# RP2350 register map
Vendor: Raspberry Pi; Series: RP; File version: 0.1
CPU: CM33 r1p0, little endian, MPU, FPU, DSP, VTOR, 4 interrupt priority bits, 52 interrupts, 8 SAU regions
Registers are 32-bit, read-write, reset 0x0 unless marked. A register's access mark holds for its fields unless they carry their own. Offsets are from the block's base; [hi:lo] are bit positions; {n}, {i} and the like mark numbered series; 'fields as' and 'values as' point back to an identical list.

## POWMAN — Controls vreg, bor, lposc, chip resets & xosc startup, powman and provides scratch register for general use and for bootcode use
Base 0x40100000
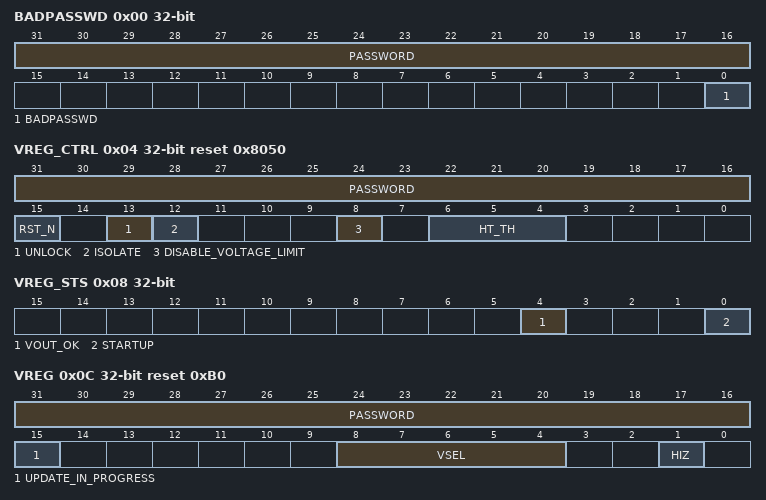
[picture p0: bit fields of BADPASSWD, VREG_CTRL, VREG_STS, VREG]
0x00 BADPASSWD — Indicates a bad password has been used
  [31:16] PASSWORD wo range 0x5AFE..0x5AFE — Write 0x5AFE with every write, or the write is ignored
    0x5AFE=PASSWORD
  [0] BADPASSWD write-1-clears
0x04 VREG_CTRL reset 0x8050 — Voltage Regulator Control
  [31:16] PASSWORD wo range 0x5AFE..0x5AFE — Write 0x5AFE with every write, or the write is ignored
    0x5AFE=PASSWORD
  [15] RST_N — returns the regulator to its startup settings 0 - reset 1 - not reset (default)
  [13] UNLOCK — unlocks the VREG control interface after power up 0 - Locked (default) 1 - Unlocked It cannot be relocked when it is unlocked.
  [12] ISOLATE — isolates the VREG control interface 0 - not isolated (default) 1 - isolated
  [8] DISABLE_VOLTAGE_LIMIT — 0=not disabled, 1=enabled
  [6:4] HT_TH — high temperature protection threshold regulator power transistors are disabled when junction temperature exceeds threshold 000 - 100C 001 - 105C 010 - 110C 011 - 115C 100 - 120C 101 - 125C 110 - 135C 111 - 150C
0x08 VREG_STS — Voltage Regulator Status
  [4] VOUT_OK ro — output regulation status 0=not in regulation, 1=in regulation
  [0] STARTUP ro — startup status 0=startup complete, 1=starting up
0x0C VREG reset 0xB0 — Voltage Regulator Settings
  [31:16] PASSWORD wo range 0x5AFE..0x5AFE — Write 0x5AFE with every write, or the write is ignored
    0x5AFE=PASSWORD
  [15] UPDATE_IN_PROGRESS ro — regulator state is being updated writes to the vreg register will be ignored when this field is set
  [8:4] VSEL — output voltage select the regulator output voltage is limited to 1.3V unless the voltage limit is disabled using the disable_voltage_limit field in the vreg_ctrl register 00000 - 0.55V 00001 - 0.60V 00010 - 0.65V 00011 - 0.70V 00100 - 0.75V 00101 - 0.80V 00110 - 0.85V 00111 - 0.90V 01000 - 0.95V 01001 - 1.00V 01010 - 1.05V 01011 - 1.10V (default) 01100 - 1.15V 01101 - 1.20V 01110 - 1.25V 01111 - 1.30V 10000 - 1.35V 10001 - 1.40V 10010 - 1.50V 10011 - 1.60V 10100 - 1.65V 10101 - 1.70V 10110 - 1.80V 10111 - 1.90V 11000 - 2.00V 11001 - 2.35V 11010 - 2.50V 11011 - 2.65V 11100 - 2.80V 11101 - 3.00V 11110 - 3.15V 11111 - 3.30V
  [1] HIZ — high impedance mode select 0=not in high impedance mode, 1=in high impedance mode
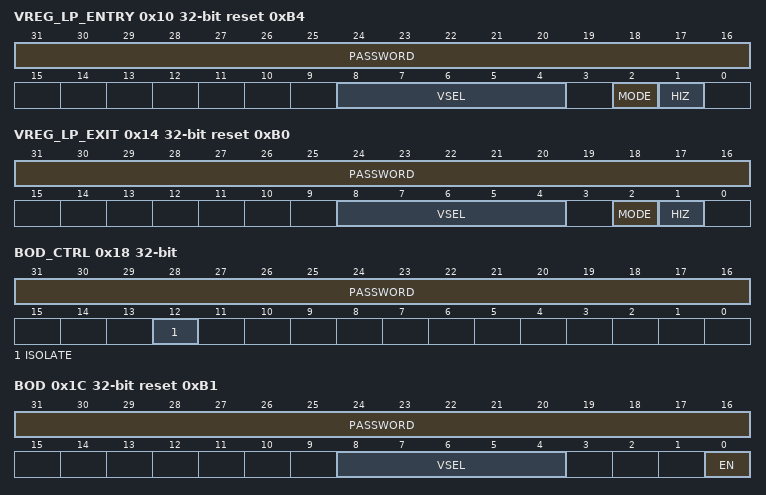
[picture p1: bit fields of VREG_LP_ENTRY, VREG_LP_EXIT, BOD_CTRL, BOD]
0x10 VREG_LP_ENTRY reset 0xB4 — Voltage Regulator Low Power Entry Settings
  [31:16] PASSWORD wo range 0x5AFE..0x5AFE — Write 0x5AFE with every write, or the write is ignored
    0x5AFE=PASSWORD
  [8:4] VSEL — output voltage select the regulator output voltage is limited to 1.3V unless the voltage limit is disabled using the disable_voltage_limit field in the vreg_ctrl register 00000 - 0.55V 00001 - 0.60V 00010 - 0.65V 00011 - 0.70V 00100 - 0.75V 00101 - 0.80V 00110 - 0.85V 00111 - 0.90V 01000 - 0.95V 01001 - 1.00V 01010 - 1.05V 01011 - 1.10V (default) 01100 - 1.15V 01101 - 1.20V 01110 - 1.25V 01111 - 1.30V 10000 - 1.35V 10001 - 1.40V 10010 - 1.50V 10011 - 1.60V 10100 - 1.65V 10101 - 1.70V 10110 - 1.80V 10111 - 1.90V 11000 - 2.00V 11001 - 2.35V 11010 - 2.50V 11011 - 2.65V 11100 - 2.80V 11101 - 3.00V 11110 - 3.15V 11111 - 3.30V
  [2] MODE — selects either normal (switching) mode or low power (linear) mode low power mode can only be selected for output voltages up to 1.3V 0 = normal mode (switching) 1 = low power mode (linear)
  [1] HIZ — high impedance mode select 0=not in high impedance mode, 1=in high impedance mode
0x14 VREG_LP_EXIT reset 0xB0 — Voltage Regulator Low Power Exit Settings
  fields as VREG_LP_ENTRY
0x18 BOD_CTRL — Brown-out Detection Control
  [31:16] PASSWORD wo range 0x5AFE..0x5AFE — Write 0x5AFE with every write, or the write is ignored
    0x5AFE=PASSWORD
  [12] ISOLATE — isolates the brown-out detection control interface 0 - not isolated (default) 1 - isolated
0x1C BOD reset 0xB1 — Brown-out Detection Settings
  [31:16] PASSWORD wo range 0x5AFE..0x5AFE — Write 0x5AFE with every write, or the write is ignored
    0x5AFE=PASSWORD
  [8:4] VSEL — threshold select 00000 - 0.473V 00001 - 0.516V 00010 - 0.559V 00011 - 0.602V 00100 - 0.645VS 00101 - 0.688V 00110 - 0.731V 00111 - 0.774V 01000 - 0.817V 01001 - 0.860V (default) 01010 - 0.903V 01011 - 0.946V 01100 - 0.989V 01101 - 1.032V 01110 - 1.075V 01111 - 1.118V 10000 - 1.161 10001 - 1.204V
  [0] EN — enable brown-out detection 0=not enabled, 1=enabled
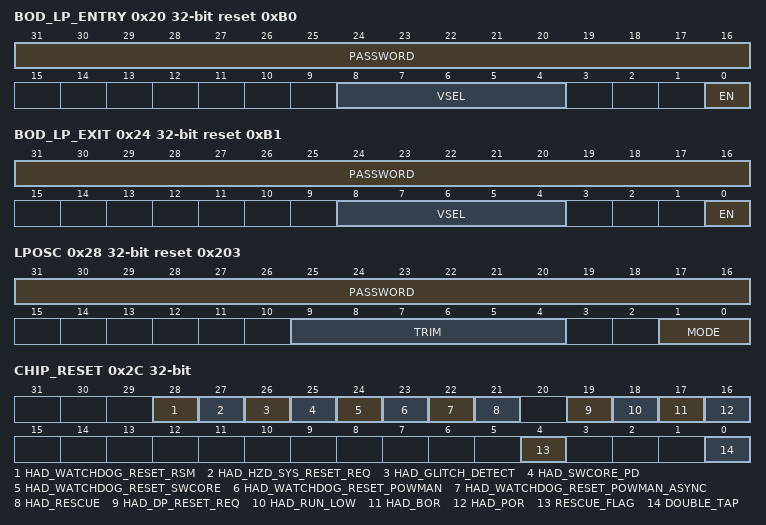
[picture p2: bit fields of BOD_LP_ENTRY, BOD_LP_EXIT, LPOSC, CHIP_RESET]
0x20 BOD_LP_ENTRY reset 0xB0 — Brown-out Detection Low Power Entry Settings
  fields as BOD
0x24 BOD_LP_EXIT reset 0xB1 — Brown-out Detection Low Power Exit Settings
  fields as BOD
0x28 LPOSC reset 0x203 — Low power oscillator control register.
  [31:16] PASSWORD wo range 0x5AFE..0x5AFE — Write 0x5AFE with every write, or the write is ignored
    0x5AFE=PASSWORD
  [9:4] TRIM — Frequency trim - the trim step is typically 1% of the reset frequency, but can be up to 3%
  [1:0] MODE — This feature has been removed
0x2C CHIP_RESET — Chip reset control and status
  [28] HAD_WATCHDOG_RESET_RSM ro — Last reset was a watchdog timeout which was configured to reset the power-on state machine This resets: double_tap flag no DP no RPAP no rescue_flag no timer no powman no swcore no psm yes and does not change the power state
  [27] HAD_HZD_SYS_RESET_REQ ro — Last reset was a system reset from the hazard debugger This resets: double_tap flag no DP no RPAP no rescue_flag no timer no powman no swcore no psm yes and does not change the power state
  [26] HAD_GLITCH_DETECT ro — Last reset was due to a power supply glitch This resets: double_tap flag no DP no RPAP no rescue_flag no timer no powman no swcore no psm yes and does not change the power state
  [25] HAD_SWCORE_PD ro — Last reset was a switched core powerdown This resets: double_tap flag no DP no RPAP no rescue_flag no timer no powman no swcore yes psm yes then starts the power sequencer
  [24] HAD_WATCHDOG_RESET_SWCORE ro — Last reset was a watchdog timeout which was configured to reset the switched-core This resets: double_tap flag no DP no RPAP no rescue_flag no timer no powman no swcore yes psm yes then starts the power sequencer
  [23] HAD_WATCHDOG_RESET_POWMAN ro — Last reset was a watchdog timeout which was configured to reset the power manager This resets: double_tap flag no DP no RPAP no rescue_flag no timer yes powman yes swcore yes psm yes then starts the power sequencer
  [22] HAD_WATCHDOG_RESET_POWMAN_ASYNC ro — Last reset was a watchdog timeout which was configured to reset the power manager asynchronously This resets: double_tap flag no DP no RPAP no rescue_flag no timer yes powman yes swcore yes psm yes then starts the power sequencer
  [21] HAD_RESCUE ro — Last reset was a rescue reset from the debugger This resets: double_tap flag no DP no RPAP no rescue_flag no, it sets this flag timer yes powman yes swcore yes psm yes then starts the power sequencer
  [19] HAD_DP_RESET_REQ ro — Last reset was an reset request from the arm debugger This resets: double_tap flag no DP no RPAP no rescue_flag yes timer yes powman yes swcore yes psm yes then starts the power sequencer
  [18] HAD_RUN_LOW ro — Last reset was from the RUN pin This resets: double_tap flag no DP yes RPAP yes rescue_flag yes timer yes powman yes swcore yes psm yes then starts the power sequencer
  [17] HAD_BOR ro — Last reset was from the brown-out detection block This resets: double_tap flag yes DP yes RPAP yes rescue_flag yes timer yes powman yes swcore yes psm yes then starts the power sequencer
  [16] HAD_POR ro — Last reset was from the power-on reset This resets: double_tap flag yes DP yes RPAP yes rescue_flag yes timer yes powman yes swcore yes psm yes then starts the power sequencer
  [4] RESCUE_FLAG write-1-clears — This is set by a rescue reset from the RP-AP. Its purpose is to halt before the bootrom before booting from flash in order to recover from a boot lock-up. The debugger can then attach once the bootrom has been halted and flash some working code that does not lock up.
  [0] DOUBLE_TAP — This flag is set by double-tapping RUN. It tells bootcode to go into the bootloader.
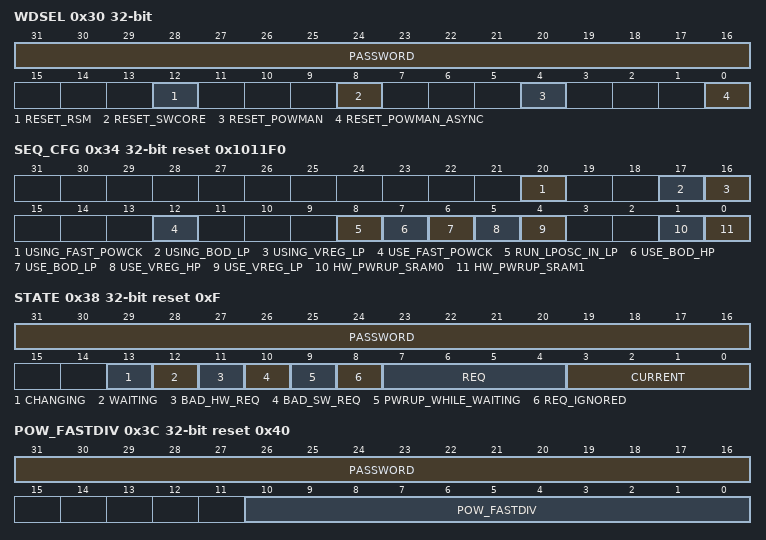
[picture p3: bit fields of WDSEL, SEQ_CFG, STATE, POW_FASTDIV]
0x30 WDSEL — Allows a watchdog reset to reset the internal state of powman in addition to the power-on state machine (PSM). Note that powman ignores watchdog resets that do not select at least the CLOCKS stage or earlier stages in the PSM. If using these bits, it's recommended to set PSM_WDSEL to all-ones in addition to the desired bits in this register. Failing to select CLOCKS or earlier will result in the POWMAN_WDSEL register having no effect.
  [31:16] PASSWORD wo range 0x5AFE..0x5AFE — Write 0x5AFE with every write, or the write is ignored
    0x5AFE=PASSWORD
  [12] RESET_RSM — If set to 1, a watchdog reset will run the full power-on state machine (PSM) sequence From a user perspective it is the same as setting RSM_WDSEL_PROC_COLD From a hardware debug perspective it has the same effect as a reset from a glitch detector
  [8] RESET_SWCORE — If set to 1, a watchdog reset will reset the switched core power domain and run the full power-on state machine (PSM) sequence From a user perspective it is the same as setting RSM_WDSEL_PROC_COLD From a hardware debug perspective it has the same effect as a power-on reset for the switched core power domain
  [4] RESET_POWMAN — If set to 1, a watchdog reset will restore powman defaults, reset the timer, reset the switched core power domain and run the full power-on state machine (PSM) sequence This relies on clk_ref running. Use reset_powman_async if that may not be true
  [0] RESET_POWMAN_ASYNC — If set to 1, a watchdog reset will restore powman defaults, reset the timer, reset the switched core domain and run the full power-on state machine (PSM) sequence This does not rely on clk_ref running
0x34 SEQ_CFG reset 0x1011F0 — For configuration of the power sequencer Writes are ignored while POWMAN_STATE_CHANGING=1
  [20] USING_FAST_POWCK ro — 0 indicates the POWMAN clock is running from the low power oscillator (32kHz) 1 indicates the POWMAN clock is running from the reference clock (2-50MHz)
  [17] USING_BOD_LP ro — Indicates the brown-out detector (BOD) mode 0 = BOD high power mode which is the default 1 = BOD low power mode
  [16] USING_VREG_LP ro — Indicates the voltage regulator (VREG) mode 0 = VREG high power mode which is the default 1 = VREG low power mode
  [12] USE_FAST_POWCK — selects the reference clock (clk_ref) as the source of the POWMAN clock when switched-core is powered. The POWMAN clock always switches to the slow clock (lposc) when switched-core is powered down because the fast clock stops running. 0 always run the POWMAN clock from the slow clock (lposc) 1 run the POWMAN clock from the fast clock when available This setting takes effect when a power up sequence is next run
  [8] RUN_LPOSC_IN_LP — Set to 0 to stop the low power osc when the switched-core is powered down, which is unwise if using it to clock the timer This setting takes effect when the swcore is next powered down
  [7] USE_BOD_HP — Set to 0 to prevent automatic switching to bod high power mode when switched-core is powered up This setting takes effect when the swcore is next powered up
  [6] USE_BOD_LP — Set to 0 to prevent automatic switching to bod low power mode when switched-core is powered down This setting takes effect when the swcore is next powered down
  [5] USE_VREG_HP — Set to 0 to prevent automatic switching to vreg high power mode when switched-core is powered up This setting takes effect when the swcore is next powered up
  [4] USE_VREG_LP — Set to 0 to prevent automatic switching to vreg low power mode when switched-core is powered down This setting takes effect when the swcore is next powered down
  [1] HW_PWRUP_SRAM0 — Specifies the power state of SRAM0 when powering up swcore from a low power state (P1.xxx) to a high power state (P0.0xx). 0=power-up 1=no change
  [0] HW_PWRUP_SRAM1 — Specifies the power state of SRAM1 when powering up swcore from a low power state (P1.xxx) to a high power state (P0.0xx). 0=power-up 1=no change
0x38 STATE reset 0xF — This register controls the power state of the 4 power domains. The current power state is indicated in POWMAN_STATE_CURRENT which is read-only. To change the state, write to POWMAN_STATE_REQ. The coding of POWMAN_STATE_CURRENT & POWMAN_STATE_REQ corresponds to the power states defined in the datasheet: bit 3 = SWCORE bit 2 = XIP cache bit 1 = SRAM0 bit 0 = SRAM1 0 = powered up 1 = powered down When POWMAN_STATE_REQ is written, the POWMAN_STATE_WAITING flag is set while the Power Manager determines what is required. If an invalid transition is requested the Power Manager will still register the request in POWMAN_STATE_REQ but will also set the POWMAN_BAD_REQ flag. It will then implement the power-up requests and ignore the power down requests. To do nothing would risk entering an unrecoverable lock-up state. Invalid requests are: any combination of power up and power down requests any request that results in swcore being powered and xip unpowered If the request is to power down the switched-core domain then POWMAN_STATE_WAITING stays active until the processors halt. During this time the POWMAN_STATE_REQ field can be re-written to change or cancel the request. When the power state transition begins the POWMAN_STATE_WAITING_flag is cleared, the POWMAN_STATE_CHANGING flag is set and POWMAN register writes are ignored until the transition completes.
  [31:16] PASSWORD wo range 0x5AFE..0x5AFE — Write 0x5AFE with every write, or the write is ignored
    0x5AFE=PASSWORD
  [13] CHANGING ro — Indicates a power state change is in progress
  [12] WAITING ro — Indicates the power manager has received a state change request and is waiting for other actions to complete before executing it
  [11] BAD_HW_REQ ro — Invalid hardware initiated state request, power up requests actioned, power down requests ignored
  [10] BAD_SW_REQ ro — Invalid software initiated state request ignored
  [9] PWRUP_WHILE_WAITING write-1-clears — Indicates that a power state change request was ignored because of a pending power state change request
  [8] REQ_IGNORED write-1-clears — Indicates that a software state change request was ignored because it clashed with an ongoing hardware or debugger request
  [7:4] REQ — This is written by software or hardware to request a new power state
  [3:0] CURRENT ro — Indicates the current power state
0x3C POW_FASTDIV reset 0x40
  [31:16] PASSWORD wo range 0x5AFE..0x5AFE — Write 0x5AFE with every write, or the write is ignored
    0x5AFE=PASSWORD
  [10:0] POW_FASTDIV — divides the POWMAN clock to provide a tick for the delay module and state machines when clk_pow is running from the slow clock it is not divided when clk_pow is running from the fast clock it is divided by tick_div
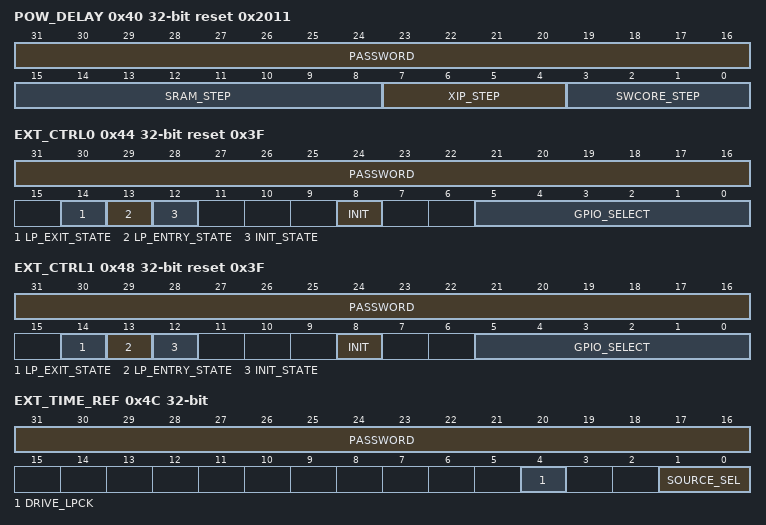
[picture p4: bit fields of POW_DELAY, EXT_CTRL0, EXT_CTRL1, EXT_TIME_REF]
0x40 POW_DELAY reset 0x2011 — power state machine delays
  [31:16] PASSWORD wo range 0x5AFE..0x5AFE — Write 0x5AFE with every write, or the write is ignored
    0x5AFE=PASSWORD
  [15:8] SRAM_STEP — timing between the sram0 and sram1 power state machine steps measured in units of the powman tick period (>=1us), 0 gives a delay of 1 unit
  [7:4] XIP_STEP — timing between the xip power state machine steps measured in units of the lposc period, 0 gives a delay of 1 unit
  [3:0] SWCORE_STEP — timing between the swcore power state machine steps measured in units of the lposc period, 0 gives a delay of 1 unit
0x44 EXT_CTRL0 reset 0x3F — Configures a gpio as a power mode aware control output
  [31:16] PASSWORD wo range 0x5AFE..0x5AFE — Write 0x5AFE with every write, or the write is ignored
    0x5AFE=PASSWORD
  [14] LP_EXIT_STATE — output level when exiting the low power state
  [13] LP_ENTRY_STATE — output level when entering the low power state
  [12] INIT_STATE
  [8] INIT
  [5:0] GPIO_SELECT — selects from gpio 0->30 set to 31 to disable this feature
0x48 EXT_CTRL1 reset 0x3F — Configures a gpio as a power mode aware control output
  fields as EXT_CTRL0
0x4C EXT_TIME_REF — Select a GPIO to use as a time reference, the source can be used to drive the low power clock at 32kHz, or to provide a 1ms tick to the timer, or provide a 1Hz tick to the timer. The tick selection is controlled by the POWMAN_TIMER register.
  [31:16] PASSWORD wo range 0x5AFE..0x5AFE — Write 0x5AFE with every write, or the write is ignored
    0x5AFE=PASSWORD
  [4] DRIVE_LPCK — Use the selected GPIO to drive the 32kHz low power clock, in place of LPOSC. This field must only be written when POWMAN_TIMER_RUN=0
  [1:0] SOURCE_SEL — 0 -> gpio12 1 -> gpio20 2 -> gpio14 3 -> gpio22
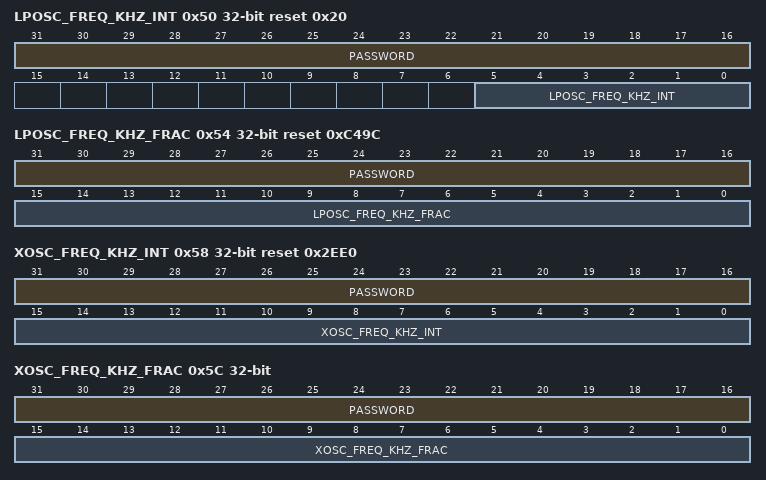
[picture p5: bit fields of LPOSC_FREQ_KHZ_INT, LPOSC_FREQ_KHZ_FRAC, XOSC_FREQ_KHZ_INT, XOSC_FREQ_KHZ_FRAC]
0x50 LPOSC_FREQ_KHZ_INT reset 0x20 — Informs the AON Timer of the integer component of the clock frequency when running off the LPOSC.
  [31:16] PASSWORD wo range 0x5AFE..0x5AFE — Write 0x5AFE with every write, or the write is ignored
    0x5AFE=PASSWORD
  [5:0] LPOSC_FREQ_KHZ_INT — Integer component of the LPOSC or GPIO clock source frequency in kHz. Default = 32 This field must only be written when POWMAN_TIMER_RUN=0 or POWMAN_TIMER_USING_XOSC=1
0x54 LPOSC_FREQ_KHZ_FRAC reset 0xC49C — Informs the AON Timer of the fractional component of the clock frequency when running off the LPOSC.
  [31:16] PASSWORD wo range 0x5AFE..0x5AFE — Write 0x5AFE with every write, or the write is ignored
    0x5AFE=PASSWORD
  [15:0] LPOSC_FREQ_KHZ_FRAC — Fractional component of the LPOSC or GPIO clock source frequency in kHz. Default = 0.768 This field must only be written when POWMAN_TIMER_RUN=0 or POWMAN_TIMER_USING_XOSC=1
0x58 XOSC_FREQ_KHZ_INT reset 0x2EE0 — Informs the AON Timer of the integer component of the clock frequency when running off the XOSC.
  [31:16] PASSWORD wo range 0x5AFE..0x5AFE — Write 0x5AFE with every write, or the write is ignored
    0x5AFE=PASSWORD
  [15:0] XOSC_FREQ_KHZ_INT — Integer component of the XOSC frequency in kHz. Default = 12000 Must be >1 This field must only be written when POWMAN_TIMER_RUN=0 or POWMAN_TIMER_USING_XOSC=0
0x5C XOSC_FREQ_KHZ_FRAC — Informs the AON Timer of the fractional component of the clock frequency when running off the XOSC.
  [31:16] PASSWORD wo range 0x5AFE..0x5AFE — Write 0x5AFE with every write, or the write is ignored
    0x5AFE=PASSWORD
  [15:0] XOSC_FREQ_KHZ_FRAC — Fractional component of the XOSC frequency in kHz. This field must only be written when POWMAN_TIMER_RUN=0 or POWMAN_TIMER_USING_XOSC=0
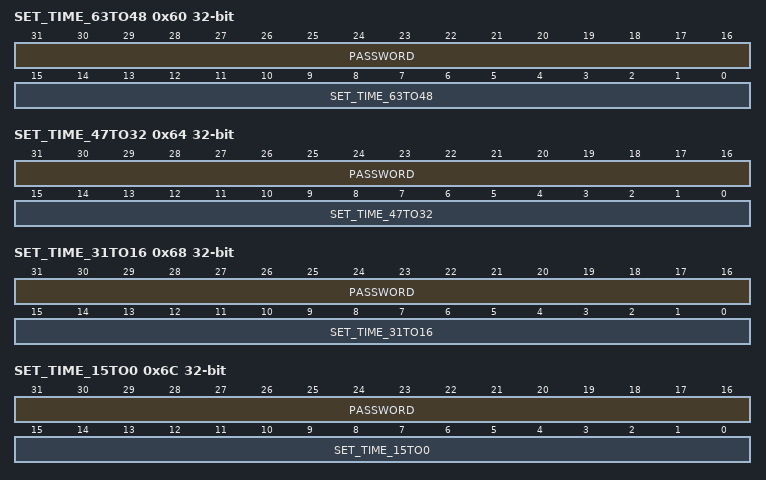
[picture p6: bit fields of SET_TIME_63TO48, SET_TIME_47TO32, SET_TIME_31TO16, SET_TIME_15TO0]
0x60 SET_TIME_63TO48
  [31:16] PASSWORD wo range 0x5AFE..0x5AFE — Write 0x5AFE with every write, or the write is ignored
    0x5AFE=PASSWORD
  [15:0] SET_TIME_63TO48 — For setting the time, do not use for reading the time, use POWMAN_READ_TIME_UPPER and POWMAN_READ_TIME_LOWER. This field must only be written when POWMAN_TIMER_RUN=0
0x64 SET_TIME_47TO32
  [31:16] PASSWORD wo range 0x5AFE..0x5AFE — Write 0x5AFE with every write, or the write is ignored
    0x5AFE=PASSWORD
  [15:0] SET_TIME_47TO32 — For setting the time, do not use for reading the time, use POWMAN_READ_TIME_UPPER and POWMAN_READ_TIME_LOWER. This field must only be written when POWMAN_TIMER_RUN=0
0x68 SET_TIME_31TO16
  [31:16] PASSWORD wo range 0x5AFE..0x5AFE — Write 0x5AFE with every write, or the write is ignored
    0x5AFE=PASSWORD
  [15:0] SET_TIME_31TO16 — For setting the time, do not use for reading the time, use POWMAN_READ_TIME_UPPER and POWMAN_READ_TIME_LOWER. This field must only be written when POWMAN_TIMER_RUN=0
0x6C SET_TIME_15TO0
  [31:16] PASSWORD wo range 0x5AFE..0x5AFE — Write 0x5AFE with every write, or the write is ignored
    0x5AFE=PASSWORD
  [15:0] SET_TIME_15TO0 — For setting the time, do not use for reading the time, use POWMAN_READ_TIME_UPPER and POWMAN_READ_TIME_LOWER. This field must only be written when POWMAN_TIMER_RUN=0
0x70 READ_TIME_UPPER
  [31:0] READ_TIME_UPPER ro — For reading bits 63:32 of the timer. When reading all 64 bits it is possible for the LOWER count to rollover during the read. It is recommended to read UPPER, then LOWER, then re-read UPPER and, if it has changed, re-read LOWER.
0x74 READ_TIME_LOWER
  [31:0] READ_TIME_LOWER ro — For reading bits 31:0 of the timer.
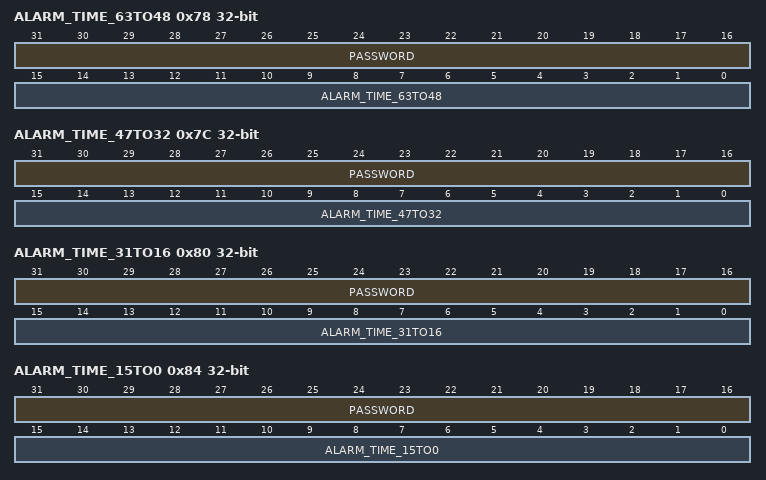
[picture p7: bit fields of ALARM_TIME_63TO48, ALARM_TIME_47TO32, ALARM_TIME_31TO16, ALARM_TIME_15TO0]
0x78 ALARM_TIME_63TO48
  [31:16] PASSWORD wo range 0x5AFE..0x5AFE — Write 0x5AFE with every write, or the write is ignored
    0x5AFE=PASSWORD
  [15:0] ALARM_TIME_63TO48 — This field must only be written when POWMAN_ALARM_ENAB=0
0x7C ALARM_TIME_47TO32
  [31:16] PASSWORD wo range 0x5AFE..0x5AFE — Write 0x5AFE with every write, or the write is ignored
    0x5AFE=PASSWORD
  [15:0] ALARM_TIME_47TO32 — This field must only be written when POWMAN_ALARM_ENAB=0
0x80 ALARM_TIME_31TO16
  [31:16] PASSWORD wo range 0x5AFE..0x5AFE — Write 0x5AFE with every write, or the write is ignored
    0x5AFE=PASSWORD
  [15:0] ALARM_TIME_31TO16 — This field must only be written when POWMAN_ALARM_ENAB=0
0x84 ALARM_TIME_15TO0
  [31:16] PASSWORD wo range 0x5AFE..0x5AFE — Write 0x5AFE with every write, or the write is ignored
    0x5AFE=PASSWORD
  [15:0] ALARM_TIME_15TO0 — This field must only be written when POWMAN_ALARM_ENAB=0
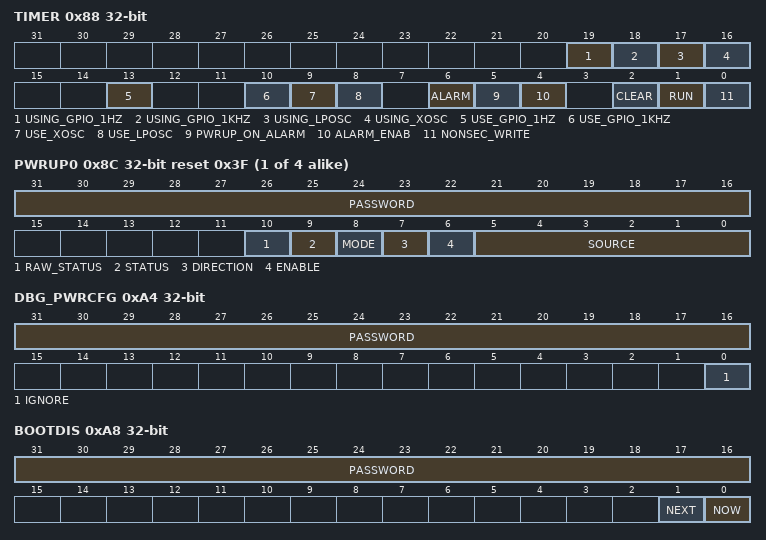
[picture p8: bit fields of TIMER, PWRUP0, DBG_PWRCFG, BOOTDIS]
0x88 TIMER
  [19] USING_GPIO_1HZ ro — Timer is synchronised to a 1hz gpio source
  [18] USING_GPIO_1KHZ ro — Timer is running from a 1khz gpio source
  [17] USING_LPOSC ro — Timer is running from lposc
  [16] USING_XOSC ro — Timer is running from xosc
  [13] USE_GPIO_1HZ — Selects the gpio source as the reference for the sec counter. The msec counter will continue to use the lposc or xosc reference.
  [10] USE_GPIO_1KHZ wo write-1-sets — switch to gpio as the source of the 1kHz timer tick
  [9] USE_XOSC wo write-1-sets — switch to xosc as the source of the 1kHz timer tick
  [8] USE_LPOSC wo write-1-sets — Switch to lposc as the source of the 1kHz timer tick
  [6] ALARM write-1-clears — Alarm has fired. Write to 1 to clear the alarm.
  [5] PWRUP_ON_ALARM — Alarm wakes the chip from low power mode
  [4] ALARM_ENAB — Enables the alarm. The alarm must be disabled while writing the alarm time.
  [2] CLEAR wo write-1-sets — Clears the timer, does not disable the timer and does not affect the alarm. This control can be written at any time.
  [1] RUN — Timer enable. Setting this bit causes the timer to begin counting up from its current value. Clearing this bit stops the timer from counting. Before enabling the timer, set the POWMAN_LPOSC_FREQ* and POWMAN_XOSC_FREQ* registers to configure the count rate, and initialise the current time by writing to SET_TIME_63TO48 through SET_TIME_15TO0. You must not write to the SET_TIME_x registers when the timer is running. Once configured, start the timer by setting POWMAN_TIMER_RUN=1. This will start the timer running from the LPOSC. When the XOSC is available switch the reference clock to XOSC then select it as the timer clock by setting POWMAN_TIMER_USE_XOSC=1
  [0] NONSEC_WRITE — Control whether Non-secure software can write to the timer registers. All other registers are hardwired to be inaccessible to Non-secure.
{0x8C+4i} PWRUP{i} reset 0x3F (i=0..3) — 4 GPIO powerup events can be configured to wake the chip up from a low power state. The pwrups are level/edge sensitive and can be set to trigger on a high/rising or low/falling event The number of gpios available depends on the package option. An invalid selection will be ignored source = 0 selects gpio0 . . source = 47 selects gpio47 source = 48 selects qspi_ss source = 49 selects qspi_sd0 source = 50 selects qspi_sd1 source = 51 selects qspi_sd2 source = 52 selects qspi_sd3 source = 53 selects qspi_sclk level = 0 triggers the pwrup when the source is low level = 1 triggers the pwrup when the source is high
  [31:16] PASSWORD wo range 0x5AFE..0x5AFE — Write 0x5AFE with every write, or the write is ignored
    0x5AFE=PASSWORD
  [10] RAW_STATUS ro — Value of selected gpio pin (only if enable == 1)
  [9] STATUS write-1-clears — Status of gpio wakeup. Write to 1 to clear a latched edge detect.
  [8] MODE — Edge or level detect. Edge will detect a 0 to 1 transition (or 1 to 0 transition). Level will detect a 1 or 0. Both types of event get latched into the current_pwrup_req register.
    0=level; 1=edge
  [7] DIRECTION
    0=low_falling; 1=high_rising
  [6] ENABLE — Set to 1 to enable the wakeup source. Set to 0 to disable the wakeup source and clear a pending wakeup event. If using edge detect a latched edge needs to be cleared by writing 1 to the status register also.
  [5:0] SOURCE
0x9C CURRENT_PWRUP_REQ — Indicates current powerup request state pwrup events can be cleared by removing the enable from the pwrup register. The alarm pwrup req can be cleared by clearing timer.alarm_enab 0 = chip reset, for the source of the last reset see POWMAN_CHIP_RESET 1 = pwrup0 2 = pwrup1 3 = pwrup2 4 = pwrup3 5 = coresight_pwrup 6 = alarm_pwrup
  [6:0] CURRENT_PWRUP_REQ ro
0xA0 LAST_SWCORE_PWRUP — Indicates which pwrup source triggered the last switched-core power up 0 = chip reset, for the source of the last reset see POWMAN_CHIP_RESET 1 = pwrup0 2 = pwrup1 3 = pwrup2 4 = pwrup3 5 = coresight_pwrup 6 = alarm_pwrup
  [6:0] LAST_SWCORE_PWRUP ro
0xA4 DBG_PWRCFG
  [31:16] PASSWORD wo range 0x5AFE..0x5AFE — Write 0x5AFE with every write, or the write is ignored
    0x5AFE=PASSWORD
  [0] IGNORE — Ignore pwrup req from debugger. If pwrup req is asserted then this will prevent power down and set powerdown blocked. Set ignore to stop paying attention to pwrup_req
0xA8 BOOTDIS — Tell the bootrom to ignore the BOOT0..3 registers following the next RSM reset (e.g. the next core power down/up). If an early boot stage has soft-locked some OTP pages in order to protect their contents from later stages, there is a risk that Secure code running at a later stage can unlock the pages by powering the core up and down. This register can be used to ensure that the bootloader runs as normal on the next power up, preventing Secure code at a later stage from accessing OTP in its unlocked state. Should be used in conjunction with the OTP BOOTDIS register.
  [31:16] PASSWORD wo range 0x5AFE..0x5AFE — Write 0x5AFE with every write, or the write is ignored
    0x5AFE=PASSWORD
  [1] NEXT — This flag always ORs writes into its current contents. It can be set but not cleared by software. The BOOTDIS_NEXT bit is OR'd into the BOOTDIS_NOW bit when the core is powered down. Simultaneously, the BOOTDIS_NEXT bit is cleared. Setting this bit means that the BOOT0..3 registers will be ignored following the next reset of the RSM by powman. This flag should be set by an early boot stage that has soft-locked OTP pages, to prevent later stages from unlocking it by power cycling.
  [0] NOW write-1-clears — When powman resets the RSM, the current value of BOOTDIS_NEXT is OR'd into BOOTDIS_NOW, and BOOTDIS_NEXT is cleared. The bootrom checks this flag before reading the BOOT0..3 registers. If it is set, the bootrom clears it, and ignores the BOOT registers. This prevents Secure software from diverting the boot path before a bootloader has had the chance to soft lock OTP pages containing sensitive data.
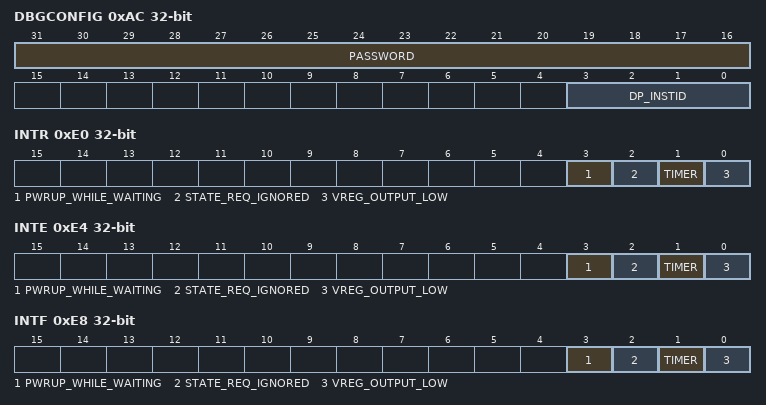
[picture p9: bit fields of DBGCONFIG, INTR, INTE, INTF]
0xAC DBGCONFIG
  [31:16] PASSWORD wo range 0x5AFE..0x5AFE — Write 0x5AFE with every write, or the write is ignored
    0x5AFE=PASSWORD
  [3:0] DP_INSTID — Configure DP instance ID for SWD multidrop selection. Recommend that this is NOT changed until you require debug access in multi-chip environment
{0xB0+4i} SCRATCH{i} (i=0..7) — Scratch register. Information persists in low power mode
{0xD0+4i} BOOT{i} (i=0..3) — Scratch register. Information persists in low power mode
0xE0 INTR — Raw Interrupts
  [3] PWRUP_WHILE_WAITING ro — Source is state.pwrup_while_waiting
  [2] STATE_REQ_IGNORED ro — Source is state.req_ignored
  [1] TIMER ro
  [0] VREG_OUTPUT_LOW write-1-clears
0xE4 INTE — Interrupt Enable
  [3] PWRUP_WHILE_WAITING — Source is state.pwrup_while_waiting
  [2] STATE_REQ_IGNORED — Source is state.req_ignored
  [1] TIMER
  [0] VREG_OUTPUT_LOW
0xE8 INTF — Interrupt Force
  fields as INTE
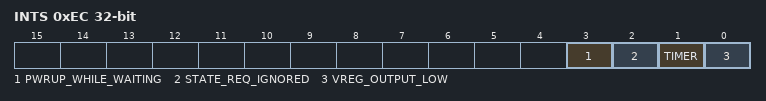
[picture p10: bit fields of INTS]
0xEC INTS — Interrupt status after masking & forcing
  [3] PWRUP_WHILE_WAITING ro — Source is state.pwrup_while_waiting
  [2] STATE_REQ_IGNORED ro — Source is state.req_ignored
  [1] TIMER ro
  [0] VREG_OUTPUT_LOW ro
